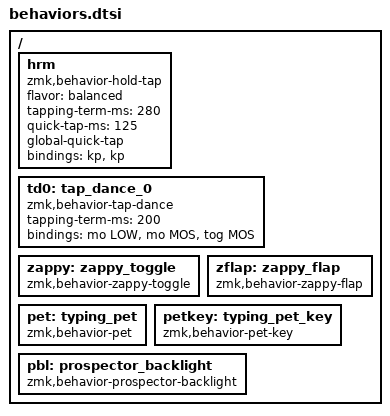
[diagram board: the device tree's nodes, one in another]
#define PET_TOGGLE 0
#define PET_FEED 1
#define PET_PLAY 2

// homerow mods
/ {
    hrm: hrm {
            compatible = "zmk,behavior-hold-tap";
            #binding-cells = <2>;
            flavor = "balanced";
            tapping-term-ms = <280>;
            quick-tap-ms = <125>;
            global-quick-tap;
            bindings = <&kp>, <&kp>;
        };

    td0: tap_dance_0 {
            compatible = "zmk,behavior-tap-dance";
            #binding-cells = <0>;
            tapping-term-ms = <200>;
            bindings = <&mo LOW>, <&mo MOS>, <&tog MOS>;
        };

    // Zappy Birds (Prospector dongle game). Drivers are built only on the
    // dongle with CONFIG_PROSPECTOR_ZAPPY_BIRDS=y; elsewhere they're inert.
    zappy: zappy_toggle {
            compatible = "zmk,behavior-zappy-toggle";
            #binding-cells = <1>;
        };

    zflap: zappy_flap {
            compatible = "zmk,behavior-zappy-flap";
            #binding-cells = <0>;
        };

    // Clackling, the typing pet (Prospector dongle). &pet CMD LAYER: swap the
    // WPM panel for the pet, feed it, or start the mini-game on capture LAYER.
    // Drivers are built only on the dongle with CONFIG_PROSPECTOR_TYPING_PET=y.
    pet: typing_pet {
            compatible = "zmk,behavior-pet";
            #binding-cells = <2>;
        };

    petkey: typing_pet_key {
            compatible = "zmk,behavior-pet-key";
            #binding-cells = <0>;
        };

    // Step the Prospector backlight (0/5/15/30/60/100, saved across reboots)
    pbl: prospector_backlight {
            compatible = "zmk,behavior-prospector-backlight";
            #binding-cells = <0>;
        };
};
